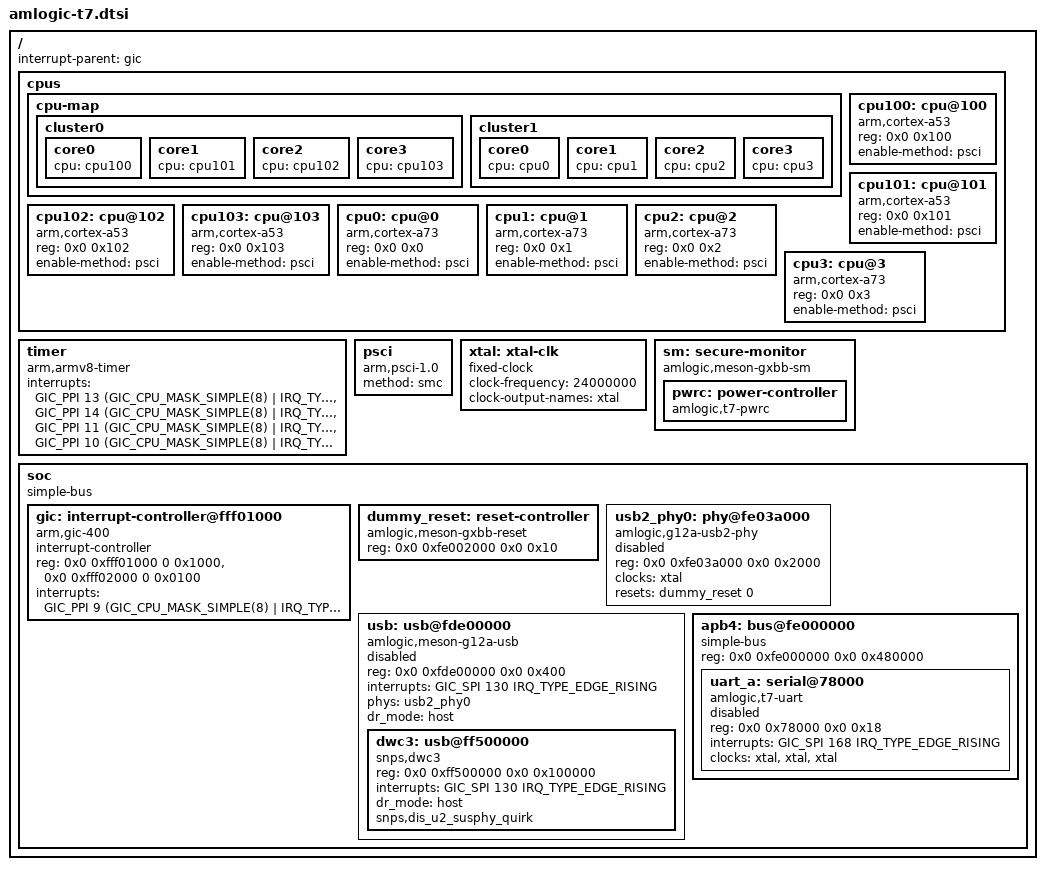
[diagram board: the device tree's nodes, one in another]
// SPDX-License-Identifier: (GPL-2.0+ OR MIT)
/*
 * Copyright (c) 2019 Amlogic, Inc. All rights reserved.
 * Adapted for Linux 6.12 Mainline (No-Header Version)
 */

#include <dt-bindings/interrupt-controller/arm-gic.h>
#include <dt-bindings/power/amlogic,t7-pwrc.h>
#include <dt-bindings/gpio/gpio.h>

/ {
	interrupt-parent = <&gic>;
	#address-cells = <2>;
	#size-cells = <2>;

	cpus {
		#address-cells = <0x2>;
		#size-cells = <0x0>;

		cpu-map {
			cluster0 {
				core0 { cpu = <&cpu100>; };
				core1 { cpu = <&cpu101>; };
				core2 { cpu = <&cpu102>; };
				core3 { cpu = <&cpu103>; };
			};
			cluster1 {
				core0 { cpu = <&cpu0>; };
				core1 { cpu = <&cpu1>; };
				core2 { cpu = <&cpu2>; };
				core3 { cpu = <&cpu3>; };
			};
		};

		cpu100: cpu@100 {
			device_type = "cpu";
			compatible = "arm,cortex-a53";
			reg = <0x0 0x100>;
			enable-method = "psci";
		};

		cpu101: cpu@101 {
			device_type = "cpu";
			compatible = "arm,cortex-a53";
			reg = <0x0 0x101>;
			enable-method = "psci";
		};

		cpu102: cpu@102 {
			device_type = "cpu";
			compatible = "arm,cortex-a53";
			reg = <0x0 0x102>;
			enable-method = "psci";
		};

		cpu103: cpu@103 {
			device_type = "cpu";
			compatible = "arm,cortex-a53";
			reg = <0x0 0x103>;
			enable-method = "psci";
		};

		cpu0: cpu@0 {
			device_type = "cpu";
			compatible = "arm,cortex-a73";
			reg = <0x0 0x0>;
			enable-method = "psci";
		};

		cpu1: cpu@1 {
			device_type = "cpu";
			compatible = "arm,cortex-a73";
			reg = <0x0 0x1>;
			enable-method = "psci";
		};

		cpu2: cpu@2 {
			device_type = "cpu";
			compatible = "arm,cortex-a73";
			reg = <0x0 0x2>;
			enable-method = "psci";
		};

		cpu3: cpu@3 {
			device_type = "cpu";
			compatible = "arm,cortex-a73";
			reg = <0x0 0x3>;
			enable-method = "psci";
		};
	};

	timer {
		compatible = "arm,armv8-timer";
		interrupts = <GIC_PPI 13 (GIC_CPU_MASK_SIMPLE(8) | IRQ_TYPE_LEVEL_LOW)>,
			     <GIC_PPI 14 (GIC_CPU_MASK_SIMPLE(8) | IRQ_TYPE_LEVEL_LOW)>,
			     <GIC_PPI 11 (GIC_CPU_MASK_SIMPLE(8) | IRQ_TYPE_LEVEL_LOW)>,
			     <GIC_PPI 10 (GIC_CPU_MASK_SIMPLE(8) | IRQ_TYPE_LEVEL_LOW)>;
	};

	psci {
		compatible = "arm,psci-1.0";
		method = "smc";
	};

	xtal: xtal-clk {
		compatible = "fixed-clock";
		clock-frequency = <24000000>;
		clock-output-names = "xtal";
		#clock-cells = <0>;
	};

	sm: secure-monitor {
		compatible = "amlogic,meson-gxbb-sm";
		pwrc: power-controller {
			compatible = "amlogic,t7-pwrc";
			#power-domain-cells = <1>;
		};
	};

	soc {
		compatible = "simple-bus";
		#address-cells = <2>;
		#size-cells = <2>;
		ranges;

		gic: interrupt-controller@fff01000 {
			compatible = "arm,gic-400";
			#interrupt-cells = <3>;
			#address-cells = <0>;
			interrupt-controller;
			reg = <0x0 0xfff01000 0 0x1000>,
			      <0x0 0xfff02000 0 0x0100>;
			interrupts = <GIC_PPI 9 (GIC_CPU_MASK_SIMPLE(8) | IRQ_TYPE_LEVEL_HIGH)>;
		};

		/* 伪造一个复位控制器，防止 PHY 驱动报错 -2 */
		dummy_reset: reset-controller {
			compatible = "amlogic,meson-gxbb-reset";
			#reset-cells = <1>;
			reg = <0x0 0xfe002000 0x0 0x10>; /* 指向一个安全的寄存器区域 */
		};

		/* USB 2.0 PHY */
		usb2_phy0: phy@fe03a000 {
			compatible = "amlogic,g12a-usb2-phy";
			reg = <0x0 0xfe03a000 0x0 0x2000>;
			#phy-cells = <0>;
			clocks = <&xtal>;
			clock-names = "xtal";
			resets = <&dummy_reset 0>; /* 必须提供一个复位信号 */
			status = "disabled";
		};

		/* USB Controller */
		usb: usb@fde00000 {
			compatible = "amlogic,meson-g12a-usb";
			reg = <0x0 0xfde00000 0x0 0x400>;
			interrupts = <GIC_SPI 130 IRQ_TYPE_EDGE_RISING>;
			#address-cells = <2>;
			#size-cells = <2>;
			ranges;

			phys = <&usb2_phy0>;
			phy-names = "usb2-phy";
			dr_mode = "host";
			status = "disabled";

			dwc3: usb@ff500000 {
				compatible = "snps,dwc3";
				reg = <0x0 0xff500000 0x0 0x100000>;
				interrupts = <GIC_SPI 130 IRQ_TYPE_EDGE_RISING>;
				dr_mode = "host";
				snps,dis_u2_susphy_quirk;
				status = "okay";
			};
		};

		apb4: bus@fe000000 {
			compatible = "simple-bus";
			reg = <0x0 0xfe000000 0x0 0x480000>;
			#address-cells = <2>;
			#size-cells = <2>;
			ranges = <0x0 0x0 0x0 0xfe000000 0x0 0x480000>;

			uart_a: serial@78000 {
				compatible = "amlogic,t7-uart", "amlogic,meson-s4-uart";
				reg = <0x0 0x78000 0x0 0x18>;
				interrupts = <GIC_SPI 168 IRQ_TYPE_EDGE_RISING>;
				clocks = <&xtal>, <&xtal>, <&xtal>;
				clock-names = "xtal", "pclk", "baud";
				status = "disabled";
			};
		};
	};
};
